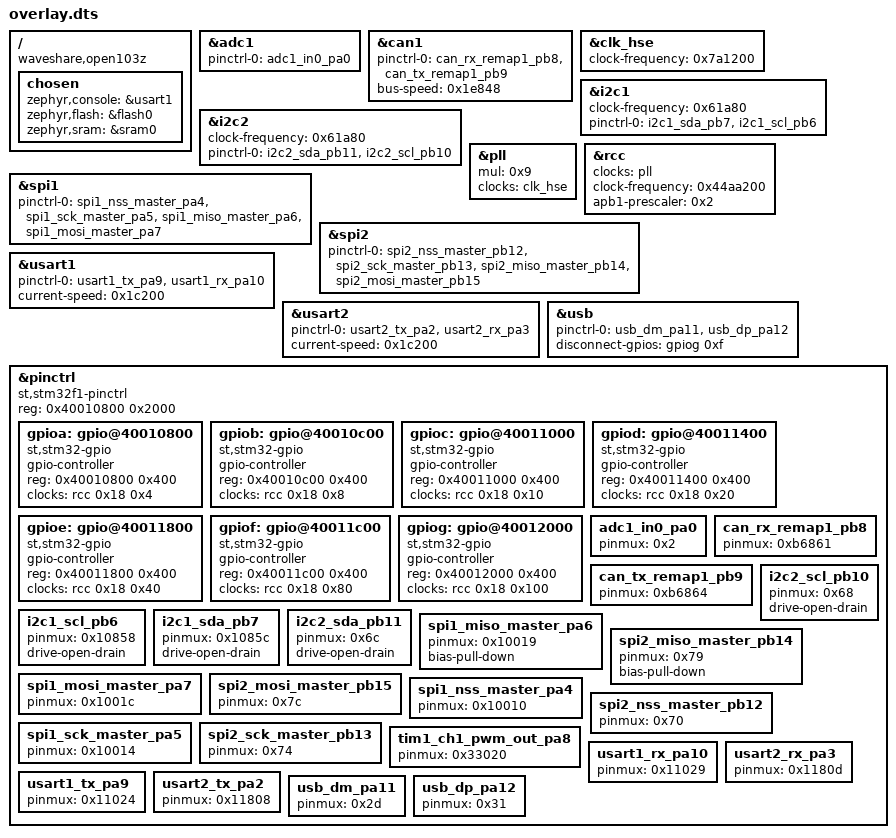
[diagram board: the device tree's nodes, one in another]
/ {
	compatible = "waveshare,open103z";
	chosen {
		zephyr,console = &usart1;
		zephyr,flash = &flash0;
		zephyr,sram = &sram0;
	};
};
&adc1{
	status = "okay";
	pinctrl-0 = < &adc1_in0_pa0 >;
	pinctrl-names = "default";
};
&can1{
	pinctrl-0 = < &can_rx_remap1_pb8 &can_tx_remap1_pb9 >;
	pinctrl-names = "default";
	bus-speed = < 0x1e848 >;
};
&clk_hse{
	status = "okay";
	clock-frequency = < 0x7a1200 >;
};
&i2c1{
	clock-frequency = < 0x61a80 >;
	status = "okay";
	pinctrl-0 = < &i2c1_sda_pb7 &i2c1_scl_pb6 >;
	pinctrl-names = "default";
};
&i2c2{
	clock-frequency = < 0x61a80 >;
	status = "okay";
	pinctrl-0 = < &i2c2_sda_pb11 &i2c2_scl_pb10 >;
	pinctrl-names = "default";
};
&pll{
	status = "okay";
	mul = < 0x9 >;
	clocks = < &clk_hse >;
};
&rcc{
	clocks = < &pll >;
	clock-frequency = < 0x44aa200 >;
	apb1-prescaler = < 0x2 >;
};
&spi1{
	status = "okay";
	pinctrl-0 = < &spi1_nss_master_pa4 &spi1_sck_master_pa5 &spi1_miso_master_pa6 &spi1_mosi_master_pa7 >;
	pinctrl-names = "default";
};
&spi2{
	status = "okay";
	pinctrl-0 = < &spi2_nss_master_pb12 &spi2_sck_master_pb13 &spi2_miso_master_pb14 &spi2_mosi_master_pb15 >;
	pinctrl-names = "default";
};
&usart1{
	status = "okay";
	pinctrl-0 = < &usart1_tx_pa9 &usart1_rx_pa10 >;
	pinctrl-names = "default";
	current-speed = < 0x1c200 >;
};
&usart2{
	status = "okay";
	pinctrl-0 = < &usart2_tx_pa2 &usart2_rx_pa3 >;
	pinctrl-names = "default";
	current-speed = < 0x1c200 >;
};
&usb{
	status = "okay";
	pinctrl-0 = < &usb_dm_pa11 &usb_dp_pa12 >;
	pinctrl-names = "default";
	disconnect-gpios = < &gpiog 0xf 0x0 >;
};
&pinctrl{
	compatible = "st,stm32f1-pinctrl";
	#address-cells = < 0x1 >;
	#size-cells = < 0x1 >;
	reg = < 0x40010800 0x2000 >;
	gpioa: gpio@40010800 {
		compatible = "st,stm32-gpio";
		gpio-controller;
		#gpio-cells = < 0x2 >;
		reg = < 0x40010800 0x400 >;
		clocks = < &rcc 0x18 0x4 >;
	};
	gpiob: gpio@40010c00 {
		compatible = "st,stm32-gpio";
		gpio-controller;
		#gpio-cells = < 0x2 >;
		reg = < 0x40010c00 0x400 >;
		clocks = < &rcc 0x18 0x8 >;
	};
	gpioc: gpio@40011000 {
		compatible = "st,stm32-gpio";
		gpio-controller;
		#gpio-cells = < 0x2 >;
		reg = < 0x40011000 0x400 >;
		clocks = < &rcc 0x18 0x10 >;
	};
	gpiod: gpio@40011400 {
		compatible = "st,stm32-gpio";
		gpio-controller;
		#gpio-cells = < 0x2 >;
		reg = < 0x40011400 0x400 >;
		clocks = < &rcc 0x18 0x20 >;
	};
	gpioe: gpio@40011800 {
		compatible = "st,stm32-gpio";
		gpio-controller;
		#gpio-cells = < 0x2 >;
		reg = < 0x40011800 0x400 >;
		clocks = < &rcc 0x18 0x40 >;
	};
	gpiof: gpio@40011c00 {
		compatible = "st,stm32-gpio";
		gpio-controller;
		#gpio-cells = < 0x2 >;
		reg = < 0x40011c00 0x400 >;
		clocks = < &rcc 0x18 0x80 >;
	};
	gpiog: gpio@40012000 {
		compatible = "st,stm32-gpio";
		gpio-controller;
		#gpio-cells = < 0x2 >;
		reg = < 0x40012000 0x400 >;
		clocks = < &rcc 0x18 0x100 >;
	};
	adc1_in0_pa0: adc1_in0_pa0 {
		pinmux = < 0x2 >;
	};
	can_rx_remap1_pb8: can_rx_remap1_pb8 {
		pinmux = < 0xb6861 >;
	};
	can_tx_remap1_pb9: can_tx_remap1_pb9 {
		pinmux = < 0xb6864 >;
	};
	i2c1_scl_pb6: i2c1_scl_pb6 {
		pinmux = < 0x10858 >;
		drive-open-drain;
	};
	i2c2_scl_pb10: i2c2_scl_pb10 {
		pinmux = < 0x68 >;
		drive-open-drain;
	};
	i2c1_sda_pb7: i2c1_sda_pb7 {
		pinmux = < 0x1085c >;
		drive-open-drain;
	};
	i2c2_sda_pb11: i2c2_sda_pb11 {
		pinmux = < 0x6c >;
		drive-open-drain;
	};
	spi1_miso_master_pa6: spi1_miso_master_pa6 {
		pinmux = < 0x10019 >;
		bias-pull-down;
	};
	spi2_miso_master_pb14: spi2_miso_master_pb14 {
		pinmux = < 0x79 >;
		bias-pull-down;
	};
	spi1_mosi_master_pa7: spi1_mosi_master_pa7 {
		pinmux = < 0x1001c >;
	};
	spi2_mosi_master_pb15: spi2_mosi_master_pb15 {
		pinmux = < 0x7c >;
	};
	spi1_nss_master_pa4: spi1_nss_master_pa4 {
		pinmux = < 0x10010 >;
	};
	spi2_nss_master_pb12: spi2_nss_master_pb12 {
		pinmux = < 0x70 >;
	};
	spi1_sck_master_pa5: spi1_sck_master_pa5 {
		pinmux = < 0x10014 >;
	};
	spi2_sck_master_pb13: spi2_sck_master_pb13 {
		pinmux = < 0x74 >;
	};
	tim1_ch1_pwm_out_pa8: tim1_ch1_pwm_out_pa8 {
		pinmux = < 0x33020 >;
	};
	usart1_rx_pa10: usart1_rx_pa10 {
		pinmux = < 0x11029 >;
	};
	usart2_rx_pa3: usart2_rx_pa3 {
		pinmux = < 0x1180d >;
	};
	usart1_tx_pa9: usart1_tx_pa9 {
		pinmux = < 0x11024 >;
	};
	usart2_tx_pa2: usart2_tx_pa2 {
		pinmux = < 0x11808 >;
	};
	usb_dm_pa11: usb_dm_pa11 {
		pinmux = < 0x2d >;
	};
	usb_dp_pa12: usb_dp_pa12 {
		pinmux = < 0x31 >;
	};
};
